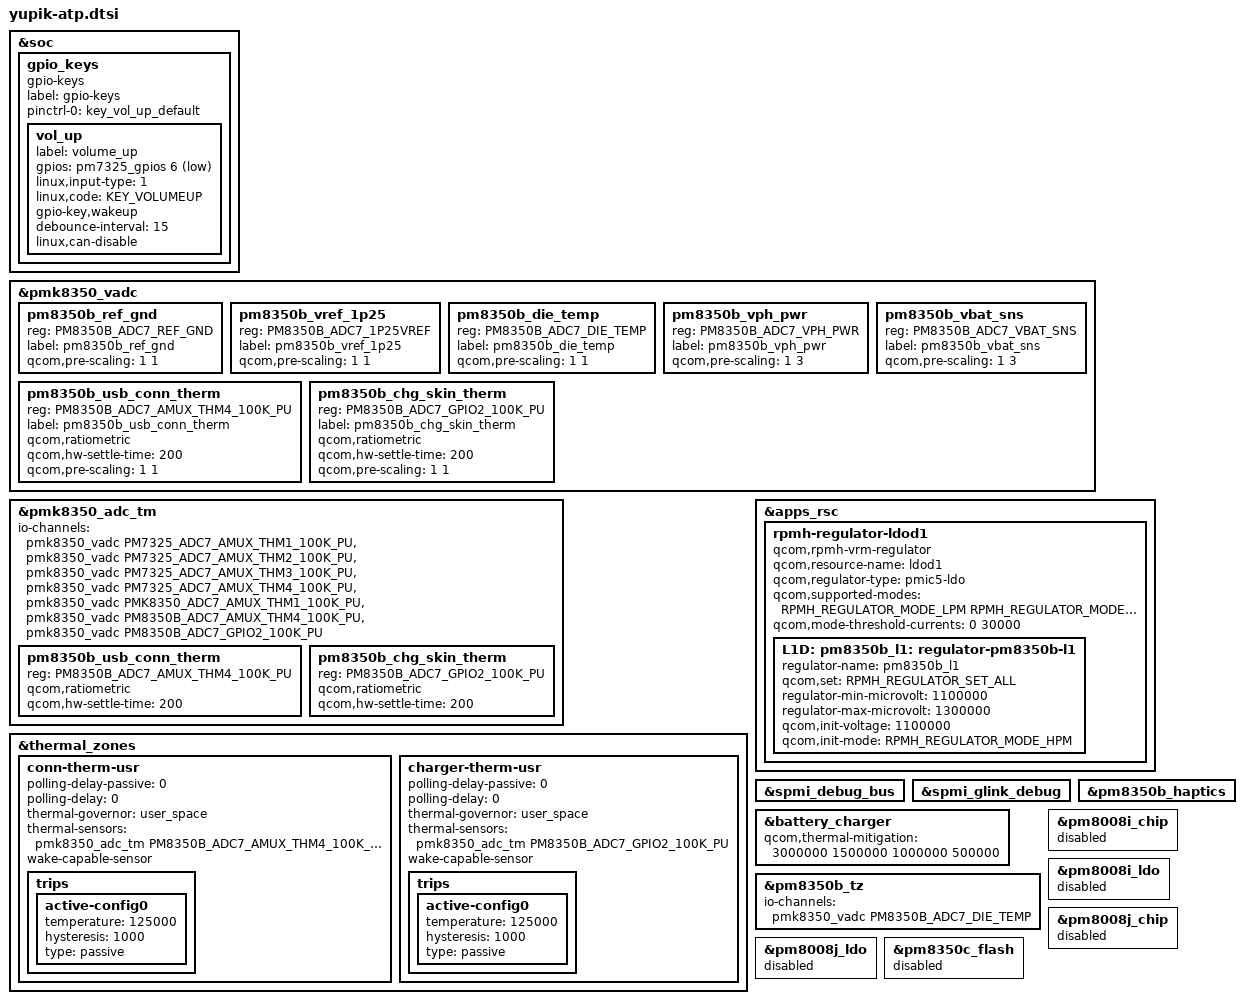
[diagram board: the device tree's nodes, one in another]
#include <dt-bindings/gpio/gpio.h>
#include <dt-bindings/regulator/qcom,rpmh-regulator-levels.h>
#include "yupik-pmic-overlay.dtsi"
#include "pm8350b.dtsi"

&soc {
	gpio_keys {
		compatible = "gpio-keys";
		label = "gpio-keys";

		pinctrl-names = "default";
		pinctrl-0 = <&key_vol_up_default>;

		vol_up {
			label = "volume_up";
			gpios = <&pm7325_gpios 6 GPIO_ACTIVE_LOW>;
			linux,input-type = <1>;
			linux,code = <KEY_VOLUMEUP>;
			gpio-key,wakeup;
			debounce-interval = <15>;
			linux,can-disable;
		};
	};
};

&pmk8350_vadc {
	pm8350b_ref_gnd {
		reg = <PM8350B_ADC7_REF_GND>;
		label = "pm8350b_ref_gnd";
		qcom,pre-scaling = <1 1>;
	};

	pm8350b_vref_1p25 {
		reg = <PM8350B_ADC7_1P25VREF>;
		label = "pm8350b_vref_1p25";
		qcom,pre-scaling = <1 1>;
	};

	pm8350b_die_temp {
		reg = <PM8350B_ADC7_DIE_TEMP>;
		label = "pm8350b_die_temp";
		qcom,pre-scaling = <1 1>;
	};

	pm8350b_vph_pwr {
		reg = <PM8350B_ADC7_VPH_PWR>;
		label = "pm8350b_vph_pwr";
		qcom,pre-scaling = <1 3>;
	};

	pm8350b_vbat_sns {
		reg = <PM8350B_ADC7_VBAT_SNS>;
		label = "pm8350b_vbat_sns";
		qcom,pre-scaling = <1 3>;
	};

	pm8350b_usb_conn_therm {
		reg = <PM8350B_ADC7_AMUX_THM4_100K_PU>;
		label = "pm8350b_usb_conn_therm";
		qcom,ratiometric;
		qcom,hw-settle-time = <200>;
		qcom,pre-scaling = <1 1>;
	};

	pm8350b_chg_skin_therm {
		reg = <PM8350B_ADC7_GPIO2_100K_PU>;
		label = "pm8350b_chg_skin_therm";
		qcom,ratiometric;
		qcom,hw-settle-time = <200>;
		qcom,pre-scaling = <1 1>;
	};
};

&pmk8350_adc_tm {
	io-channels = <&pmk8350_vadc PM7325_ADC7_AMUX_THM1_100K_PU>,
			<&pmk8350_vadc PM7325_ADC7_AMUX_THM2_100K_PU>,
			<&pmk8350_vadc PM7325_ADC7_AMUX_THM3_100K_PU>,
			<&pmk8350_vadc PM7325_ADC7_AMUX_THM4_100K_PU>,
			<&pmk8350_vadc PMK8350_ADC7_AMUX_THM1_100K_PU>,
			<&pmk8350_vadc PM8350B_ADC7_AMUX_THM4_100K_PU>,
			<&pmk8350_vadc PM8350B_ADC7_GPIO2_100K_PU>;

	pm8350b_usb_conn_therm {
		reg = <PM8350B_ADC7_AMUX_THM4_100K_PU>;
		qcom,ratiometric;
		qcom,hw-settle-time = <200>;
	};

	pm8350b_chg_skin_therm {
		reg = <PM8350B_ADC7_GPIO2_100K_PU>;
		qcom,ratiometric;
		qcom,hw-settle-time = <200>;
	};
};

&thermal_zones {
	conn-therm-usr {
		polling-delay-passive = <0>;
		polling-delay = <0>;
		thermal-governor = "user_space";
		thermal-sensors = <&pmk8350_adc_tm PM8350B_ADC7_AMUX_THM4_100K_PU>;
		wake-capable-sensor;
		trips {
			active-config0 {
				temperature = <125000>;
				hysteresis = <1000>;
				type = "passive";
			};
		};
	};

	charger-therm-usr {
		polling-delay-passive = <0>;
		polling-delay = <0>;
		thermal-governor = "user_space";
		thermal-sensors = <&pmk8350_adc_tm PM8350B_ADC7_GPIO2_100K_PU>;
		wake-capable-sensor;
		trips {
			active-config0 {
				temperature = <125000>;
				hysteresis = <1000>;
				type = "passive";
			};
		};
	};
};

&apps_rsc {
	rpmh-regulator-ldod1 {
		compatible = "qcom,rpmh-vrm-regulator";
		qcom,resource-name = "ldod1";
		qcom,regulator-type = "pmic5-ldo";
		qcom,supported-modes =
			<RPMH_REGULATOR_MODE_LPM
			RPMH_REGULATOR_MODE_HPM>;
		qcom,mode-threshold-currents = <0 30000>;
		L1D:
		pm8350b_l1: regulator-pm8350b-l1 {
			regulator-name = "pm8350b_l1";
			qcom,set = <RPMH_REGULATOR_SET_ALL>;
			regulator-min-microvolt = <1100000>;
			regulator-max-microvolt = <1300000>;
			qcom,init-voltage = <1100000>;
			qcom,init-mode = <RPMH_REGULATOR_MODE_HPM>;
		};
	};
};

&spmi_debug_bus {
	status = "ok";
};

&spmi_glink_debug {
	status = "ok";
};

&pm8350b_haptics {
	status = "ok";
};

&battery_charger {
	qcom,thermal-mitigation = <3000000 1500000 1000000 500000>;
};

&pm8350b_tz {
	io-channels = <&pmk8350_vadc PM8350B_ADC7_DIE_TEMP>;
	io-channel-names = "thermal";
};

&pm8008i_chip {
	status = "disabled";
};

&pm8008i_ldo {
	status = "disabled";
};

&pm8008j_chip {
	status = "disabled";
};

&pm8008j_ldo {
	status = "disabled";
};

&pm8350c_flash {
	status = "disabled";
};
